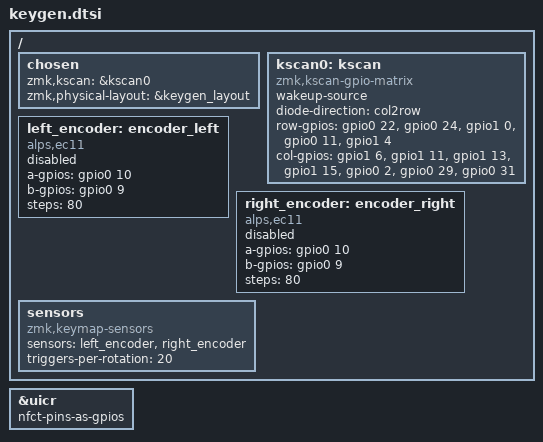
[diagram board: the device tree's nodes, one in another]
/*
 * Keygen: both halves. Pins follow tools/gen_schematic.py (MCU_PINS, MCU_NETS); the controller
 * is a nice!nano v2, so pins are written as nRF52840 GPIOs rather than Pro Micro numbers.
 */

#include "keygen-layouts.dtsi"

/ {
    chosen {
        zmk,kscan = &kscan0;
        zmk,physical-layout = &keygen_layout;
    };

    /* 5 x 7 per half, COL2ROW: switch to the column, diode cathode to the row */
    kscan0: kscan {
        compatible = "zmk,kscan-gpio-matrix";
        wakeup-source;
        diode-direction = "col2row";

        row-gpios
            = <&gpio0 22 (GPIO_ACTIVE_HIGH | GPIO_PULL_DOWN)>   /* ROW0, pad 7  */
            , <&gpio0 24 (GPIO_ACTIVE_HIGH | GPIO_PULL_DOWN)>   /* ROW1, pad 8  */
            , <&gpio1 0  (GPIO_ACTIVE_HIGH | GPIO_PULL_DOWN)>   /* ROW2, pad 9  */
            , <&gpio0 11 (GPIO_ACTIVE_HIGH | GPIO_PULL_DOWN)>   /* ROW3, pad 10 */
            , <&gpio1 4  (GPIO_ACTIVE_HIGH | GPIO_PULL_DOWN)>   /* ROW4, pad 11 */
            ;
        col-gpios                                               /* COL0 is the outer edge */
            = <&gpio1 6  GPIO_ACTIVE_HIGH>                      /* COL0, pad 12 */
            , <&gpio1 11 GPIO_ACTIVE_HIGH>                      /* COL1, pad 22 */
            , <&gpio1 13 GPIO_ACTIVE_HIGH>                      /* COL2, pad 21 */
            , <&gpio1 15 GPIO_ACTIVE_HIGH>                      /* COL3, pad 20 */
            , <&gpio0 2  GPIO_ACTIVE_HIGH>                      /* COL4, pad 19 */
            , <&gpio0 29 GPIO_ACTIVE_HIGH>                      /* COL5, pad 18 */
            , <&gpio0 31 GPIO_ACTIVE_HIGH>                      /* COL6, pad 17 */
            ;
    };

    /* An EC11 on each half, on the same pins; each push switch is in its half's matrix at
     * row 0 / column 6. Each half's overlay enables its own. */
    left_encoder: encoder_left {
        compatible = "alps,ec11";
        a-gpios = <&gpio0 10 (GPIO_ACTIVE_HIGH | GPIO_PULL_UP)>;   /* ENC_A, pad 23 (NFC2) */
        b-gpios = <&gpio0 9  (GPIO_ACTIVE_HIGH | GPIO_PULL_UP)>;   /* ENC_B, pad 24 (NFC1) */
        steps = <80>;
        status = "disabled";
    };

    right_encoder: encoder_right {
        compatible = "alps,ec11";
        a-gpios = <&gpio0 10 (GPIO_ACTIVE_HIGH | GPIO_PULL_UP)>;   /* ENC_A, pad 23 (NFC2) */
        b-gpios = <&gpio0 9  (GPIO_ACTIVE_HIGH | GPIO_PULL_UP)>;   /* ENC_B, pad 24 (NFC1) */
        steps = <80>;
        status = "disabled";
    };

    sensors: sensors {
        compatible = "zmk,keymap-sensors";
        sensors = <&left_encoder &right_encoder>;
        triggers-per-rotation = <20>;
    };
};

/* Both encoder lines are on the NFC pins */
&uicr {
    nfct-pins-as-gpios;
};
